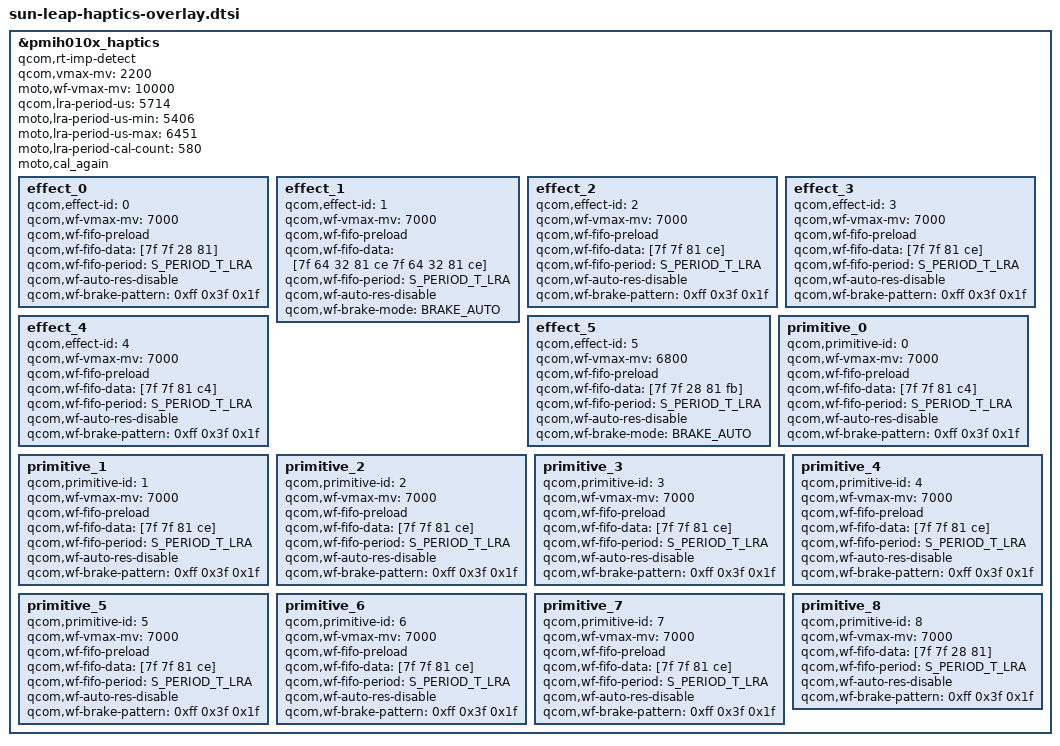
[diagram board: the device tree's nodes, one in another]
/* Copyright (c) 2024, The Linux Foundation. All rights reserved.
 *
 * This program is free software; you can redistribute it and/or modify
 * it under the terms of the GNU General Public License version 2 and
 * only version 2 as published by the Free Software Foundation.
 *
 * This program is distributed in the hope that it will be useful,
 * but WITHOUT ANY WARRANTY; without even the implied warranty of
 * MERCHANTABILITY or FITNESS FOR A PARTICULAR PURPOSE.  See the
 * GNU General Public License for more details.
 */

&pmih010x_haptics {
	qcom,rt-imp-detect;
	qcom,vmax-mv = <2200>;
	moto,wf-vmax-mv = <10000>;
	qcom,lra-period-us = <5714>;
	moto,lra-period-us-min = <5406>;
	moto,lra-period-us-max = <6451>;
	moto,lra-period-cal-count = <580>;
	moto,cal_again;
	status = "ok";

	effect_0 {
		/* CLICK */
		qcom,effect-id = <0>;
		qcom,wf-vmax-mv = <7000>;
		qcom,wf-fifo-preload;
		qcom,wf-fifo-data = [7f 7f 28 81];
		qcom,wf-fifo-period = <S_PERIOD_T_LRA>;
		qcom,wf-auto-res-disable;
		qcom,wf-brake-pattern = /bits/ 8 <0xff 0x3f 0x1f>;
		/delete-property/ qcom,wf-brake-disable;
	};

	effect_1 {
		/* DOUBLE_CLICK */
		qcom,effect-id = <1>;
		qcom,wf-vmax-mv = <7000>;
		qcom,wf-fifo-preload;
		qcom,wf-fifo-data = [7f 64 32 81 ce 7f 64 32 81 ce];
		qcom,wf-fifo-period = <S_PERIOD_T_LRA>;
		qcom,wf-auto-res-disable;
		qcom,wf-brake-mode = <BRAKE_AUTO>;
		/delete-property/ qcom,wf-brake-disable;
	};

	effect_2 {
		/* TICK */
		qcom,effect-id = <2>;
		qcom,wf-vmax-mv = <7000>;
		qcom,wf-fifo-preload;
		qcom,wf-fifo-data = [7f 7f 81 ce];
		qcom,wf-fifo-period = <S_PERIOD_T_LRA>;
		qcom,wf-auto-res-disable;
		qcom,wf-brake-pattern = /bits/ 8 <0xff 0x3f 0x1f>;
		/delete-property/ qcom,wf-brake-disable;
	};

	effect_3 {
		/* THUD */
		qcom,effect-id = <3>;
		qcom,wf-vmax-mv = <7000>;
		qcom,wf-fifo-preload;
		qcom,wf-fifo-data = [7f 7f 81 ce];
		qcom,wf-fifo-period = <S_PERIOD_T_LRA>;
		qcom,wf-auto-res-disable;
		qcom,wf-brake-pattern = /bits/ 8 <0xff 0x3f 0x1f>;
		/delete-property/ qcom,wf-brake-disable;
	};

	effect_4 {
		/* POP */
		qcom,effect-id = <4>;
		qcom,wf-vmax-mv = <7000>;
		qcom,wf-fifo-preload;
		qcom,wf-fifo-data = [7f 7f 81 c4];
		qcom,wf-fifo-period = <S_PERIOD_T_LRA>;
		qcom,wf-auto-res-disable;
		qcom,wf-brake-pattern = /bits/ 8 <0xff 0x3f 0x1f>;
		/delete-property/ qcom,wf-brake-disable;
	};

	effect_5 {
		/* HEAVY_CLICK */
		qcom,effect-id = <5>;
		qcom,wf-vmax-mv = <6800>;
		qcom,wf-fifo-preload;
		qcom,wf-fifo-data = [7f 7f 28 81 fb];
		qcom,wf-fifo-period = <S_PERIOD_T_LRA>;
		qcom,wf-auto-res-disable;
		qcom,wf-brake-mode = <BRAKE_AUTO>;
		/delete-property/ qcom,wf-brake-disable;
	};

	primitive_0 {
		/* NOOP */
		qcom,primitive-id = <0>;
		qcom,wf-vmax-mv = <7000>;
		qcom,wf-fifo-preload;
		qcom,wf-fifo-data = [7f 7f 81 c4];
		qcom,wf-fifo-period = <S_PERIOD_T_LRA>;
		qcom,wf-auto-res-disable;
		qcom,wf-brake-pattern = /bits/ 8 <0xff 0x3f 0x1f>;
		/delete-property/ qcom,wf-brake-disable;
	};

	primitive_1 {
		/* CLICK */
		qcom,primitive-id = <1>;
		qcom,wf-vmax-mv = <7000>;
		qcom,wf-fifo-preload;
		qcom,wf-fifo-data = [7f 7f 81 ce];
		qcom,wf-fifo-period = <S_PERIOD_T_LRA>;
		qcom,wf-auto-res-disable;
		qcom,wf-brake-pattern = /bits/ 8 <0xff 0x3f 0x1f>;
		/delete-property/ qcom,wf-brake-disable;
	};

	primitive_2 {
		/* THUD */
		qcom,primitive-id = <2>;
		qcom,wf-vmax-mv = <7000>;
		qcom,wf-fifo-preload;
		qcom,wf-fifo-data = [7f 7f 81 ce];
		qcom,wf-fifo-period = <S_PERIOD_T_LRA>;
		qcom,wf-auto-res-disable;
		qcom,wf-brake-pattern = /bits/ 8 <0xff 0x3f 0x1f>;
		/delete-property/ qcom,wf-brake-disable;
	};

	primitive_3 {
		/* SPIN */
		qcom,primitive-id = <3>;
		qcom,wf-vmax-mv = <7000>;
		qcom,wf-fifo-preload;
		qcom,wf-fifo-data = [7f 7f 81 ce];
		qcom,wf-fifo-period = <S_PERIOD_T_LRA>;
		qcom,wf-auto-res-disable;
		qcom,wf-brake-pattern = /bits/ 8 <0xff 0x3f 0x1f>;
		/delete-property/ qcom,wf-brake-disable;
	};

	primitive_4 {
		/* QUICK_RISE */
		qcom,primitive-id = <4>;
		qcom,wf-vmax-mv = <7000>;
		qcom,wf-fifo-preload;
		qcom,wf-fifo-data = [7f 7f 81 ce];
		qcom,wf-fifo-period = <S_PERIOD_T_LRA>;
		qcom,wf-auto-res-disable;
		qcom,wf-brake-pattern = /bits/ 8 <0xff 0x3f 0x1f>;
		/delete-property/ qcom,wf-brake-disable;
	};

	primitive_5 {
		/* SLOW_RISE */
		qcom,primitive-id = <5>;
		qcom,wf-vmax-mv = <7000>;
		qcom,wf-fifo-preload;
		qcom,wf-fifo-data = [7f 7f 81 ce];
		qcom,wf-fifo-period = <S_PERIOD_T_LRA>;
		qcom,wf-auto-res-disable;
		qcom,wf-brake-pattern = /bits/ 8 <0xff 0x3f 0x1f>;
		/delete-property/ qcom,wf-brake-disable;
	};

	primitive_6 {
		/* QUICK_FALL */
		qcom,primitive-id = <6>;
		qcom,wf-vmax-mv = <7000>;
		qcom,wf-fifo-preload;
		qcom,wf-fifo-data = [7f 7f 81 ce];
		qcom,wf-fifo-period = <S_PERIOD_T_LRA>;
		qcom,wf-auto-res-disable;
		qcom,wf-brake-pattern = /bits/ 8 <0xff 0x3f 0x1f>;
		/delete-property/ qcom,wf-brake-disable;
	};

	primitive_7 {
		/* LIGHT_TICK */
		qcom,primitive-id = <7>;
		qcom,wf-vmax-mv = <7000>;
		qcom,wf-fifo-preload;
		qcom,wf-fifo-data = [7f 7f 81 ce];
		qcom,wf-fifo-period = <S_PERIOD_T_LRA>;
		qcom,wf-auto-res-disable;
		qcom,wf-brake-pattern = /bits/ 8 <0xff 0x3f 0x1f>;
		/delete-property/ qcom,wf-brake-disable;
	};

	primitive_8 {
		/* LOW_TICK */
		qcom,primitive-id = <8>;
		qcom,wf-vmax-mv = <7000>;
		/delete-property/ qcom,wf-fifo-preload;
		qcom,wf-fifo-data = [7f 7f 28 81];
		qcom,wf-fifo-period = <S_PERIOD_T_LRA>;
		qcom,wf-auto-res-disable;
		qcom,wf-brake-pattern = /bits/ 8 <0xff 0x3f 0x1f>;
		/delete-property/ qcom,wf-brake-disable;
	};

};
